# YTM32B1MD2 register map
Vendor: YTMicro; File version: 1.0
CPU: CM33 r0p4, little endian, MPU, FPU, 2 interrupt priority bits
Registers are 32-bit, read-write, reset 0x0 unless marked. A register's access mark holds for its fields unless they carry their own. Offsets are from the block's base; [hi:lo] are bit positions; {n}, {i} and the like mark numbered series; 'fields as' and 'values as' point back to an identical list; <NAME> marks a mode.

## EFM — Embedded Flash Module
Base 0x40010000; register names take the prefix EFM_
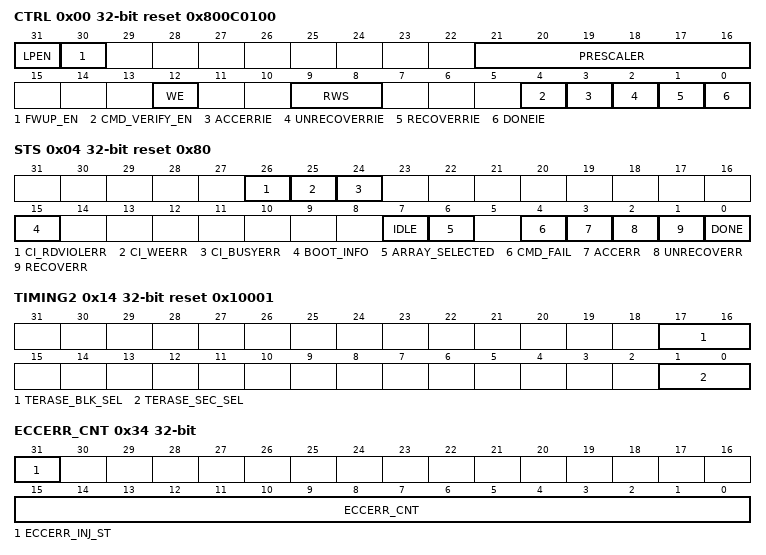
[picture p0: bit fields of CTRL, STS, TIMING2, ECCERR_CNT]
0x00 CTRL reset 0x800C0100
  [31] LPEN — This LPEN bit determines whether the Flash array will enter low power mode when the MCU send a low power request. ewline This field is reset by System Reset.
    0=Flash will keep active when the MCU send a low power request; 1=Flash will enter low power mode when the MCU send a low power request
  [30] FWUP_EN — This FWUP_EN bit determines whether enables fast wake-up of the Flash array. Power consumption of fast wake-up is bigger than normal wake-up. ewline This field is reset by System Reset.
    0=Flash wake-up time from Deep Standby mode is 20us; 1=Flash wake-up time from Deep Standby mode is 10us
  [21:16] PRESCALER — These PRESCALER bits are used for EFM operation time control. ewline Please use the following equation to calculate the PRESCALER value: ewline PRESCALER = Slow Bus Clock frequency / 2 ewline Round up if not divisible. ewline The unit of Slow Bus Clock frequency is Mhz. ewline For example, if Slow Bus Clock frequency is 40Mhz, PRESCALER value should be 20. ewline If Slow Bus Clock frequency is 23Mhz, PRESCALER value should be 12. ewline Please re-configure PRESCALER once the frequency is changed. ewline This field is reset by System Reset.
  [12] WE — This WE bit determines whether Flash is writable. Write Flash when WE is low causes bus error and STS[CI_WEERR] flag is set at the same time . ewline In the command operation flow, please set WE before AHB write and clear WE after AHB write . ewline This field is reset by System Reset.
    0=Disable Flash write; 1=Enable Flash write
  [9:8] RWS
    0=Valid value for core clk <= 40Mhz. in Normal Read mode; 1=Valid value for core clk <= 80Mhz. in Normal Read mode; 2=Valid value for core clk <= 100Mhz in Normal Read mode; 3=Valid value for core clk <= 100Mhz. in Normal Read mode
  [4] CMD_VERIFY_EN — This CMD_VERIFY_EN bit determines whether to do verify read after erase or program operation during executing a command. ewline - After each program cycle, if CMD_VERIFY_EN=1, EFM read the programmed address and compare the read data to program data. If not equal, set STS[CMD_FAIL] flag high ewline - After each erase cycle, if CMD_VERIFY_EN=1, EFM read the erased addresses and compare read data with FF. If read data are not all FF, set STS[CMD_FAIL] flag high. ewline This field is reset by System Reset.
    0=Disable verify read after erase or program cycle; 1=Enable verify read after erase or program cycle
  [3] ACCERRIE — This ACCERRIE bit determines whether the interrupt will be generated when STS[ACCERR] flag is asserted. ewline This field is reset by System Reset.
    0=Don't generate interrupt when STS[ACCERR] flag is asserted; 1=Generate interrupt when STS[ACCERR] flag is asserted
  [2] UNRECOVERRIE — This UNRECOVERRIE bit determines whether the interrupt will be generated when STS[UNRECOVERR] flag is asserted. ewline This field is reset by System Reset.
    0=Don't generate interrupt when STS[UNRECOVERR] flag is asserted; 1=Generate interrupt when STS[UNRECOVERR] flag is asserted
  [1] RECOVERRIE — This RECOVERRIE bit determines whether the interrupt will be generated when STS[RECOVERR] flag is asserted. ewline This field is reset by System Reset.
    0=Don't generate interrupt when STS[RECOVER] flag is asserted; 1=Generate interrupt when STS[RECOVERR] flag is asserted
  [0] DONEIE — This DONEIE bit determines whether the interrupt will be generated when DONE flag is asserted. ewline This field is reset by System Reset.
    0=Don't generate interrupt when STS[DONE] flag is asserted; 1=Generate interrupt when STS[DONE] flag is asserted
0x04 STS reset 0x80
  [26] CI_RDVIOLERR — This CI_RDVIOLERR bit indicates whether a read violation error is detected. Please check this bit after bus error. ewline Read violation error includes below scenarios: ewline - Read CUS_NVR sector when CUS_KEY is not set. ewline - Read HCU_NVR sector. ewline - Read BOOT_NVR sector. ewline This field is reset by System Reset.
  [25] CI_WEERR — Try to write Flash array when CTRL[WE] is disabled will cause bus error and set CI_WEERR flag. ewline This field is reset by System Reset.
  [24] CI_BUSYERR — Try to access Flash array when CTRL[IDLE] is 0 will cause bus error and set CI_BUSYERR flag. ewline This field is reset by System Reset.
  [15] BOOT_INFO ro — This BOOT_INFO bit indicates whether PFlash SoC address remap is enabled. ewline This field is reset by System Reset.
    0=PFlash SoC address remap is disabled, SoC boots code from A side; 1=PFlash SoC address remap is enabled, SoC boots code from B side. Refer to \hyperref[boot-swap-operation]{Boot-Swap Operation} for more details.
  [7] IDLE ro — This IDLE bit indicates whether EFM is busy executing a command or initializing or in low power mode. ewline IDLE bit may not be low immediately after writing a command because EFM needs to wait for core interface free before starting execute the command. This field is reset by System Reset.
    0=EFM is executing a command or initializing or in low power mode; 1=EFM is idle
  [6] ARRAY_SELECTED ro — Software should write target array address before launching a command. The write operation will set ARRAY_SELECTED flag after several cycles. ewline This field is reset by System Reset. ewline ote{Launching command when ARRAY_SELECTED=1 avoid access error caused by non-sequential scheduling of instructions.}
    0=The target Flash array is not selected. EFM is not ready to launch a command.; 1=The target Flash array is selected. EFM is ready to launch a command.
  [4] CMD_FAIL — This CMD_FAIL bit indicates whether the current command is failed. ewline ewline Command failure includes below scenarios: ewline - Read check before a program cycle failed if Flash line bits are not all FF. ewline - Verify check after an erase cycle failed if Flash line bits are not cleared to all FF. ewline - Verify check after a program cycle failed if program data not equal to read data. ewline ewline This field is reset by System Reset.
  [3] ACCERR — This ACCERR bit indicates whether an access error is detected. ewline This flag is set if detecting an error when write CMD register. ewline If an access error occurred, the command is not launched. ewline Access error scenarios refer to \hyperref[flash-abnormal-operation]{Flash Abnormal Operation}. ewline This field is reset by System Reset.
    0=Access error is not detected; 1=Access error is detected
  [2] UNRECOVERR — This UNRECOVERR bit indicates whether a 2-bit ECC error is detected during Flash read. ewline This field is reset by Power-on Reset.
    0=No un-recovery ECC error is detected; 1=At least one un-recovery ECC error is detected
  [1] RECOVERR — This RECOVERR bit indicates whether a 1-bit ECC error is detected during Flash read. ewline This field is reset by Power-on Reset.
    0=No recovery ECC error is detected; 1=At least one recovery error is detected
  [0] DONE — This DONE bit indicates whether the current command is completed. ewline This field is reset by System Reset.
    0=Current command is in progress or no command is launched; 1=Current command is completed
0x08 CMD
  [7:0] CMD — These CMD bits determine which commands are available. Write valid command code to CMD to launch a command. ewline Refer to table \hyperref[efm-commands]{EFM commands} for command code. ewline This field is reset by System Reset.
0x0C CMD_PROT
  [31:0] CMD_PROT — These CMD_PROT is used to disable commands. ewline If any bit of CMD_PROT is set high, its corresponding command is disabled. ewline Refer to \hyperref[efm-commands]{EFM commands} table for the map between commands and CMD_PROT bits ewline This field is reset by System Reset.
0x10 TIMING1 reset 0x1
  [1:0] TPROG_SEL — These TPROG_SEL bits indicate the program pulse time. ewline The valid program pulse time is from 5us to 6.5us. Specific program time is decided by TPROG_SEL by fixed step. ewline For example, if TPROG_SEL is 01, the Flash array program pulse time is 5.5us. ewline This register bit is reset by System Reset.
    0=Flash array program pulse time is 5us; 1=Flash array program pulse time is 5.5us; 2=Flash array program pulse time is 6us; 3=Flash array program pulse time is 6.5us
0x14 TIMING2 reset 0x10001
  [17:16] TERASE_BLK_SEL — These TERASE_BLK_SEL bits indicate the block erase pulse times. ewline The valid block erase pulse time is from 30ms to 40ms. Specific block erase time is decided by TERASE_BLK_SEL. ewline For example, if TERASE_BLK_SEL value is 01, the Flash array block erase pulse time is 34ms. ewline This register bit is reset by System Reset. ote{Please set TERASE_BLK_SEL register to valid value before send ERASE_BLOCK command.}
    0=Flash array block erase pulse time is 31ms; 1=Flash array block erase pulse time is 34ms; 2=Flash array block erase pulse time is 36ms; 3=Flash array block erase pulse time is 39ms
  [1:0] TERASE_SEC_SEL — These TERASE_SEC_SEL bits indicate the sector erase pulse times. ewline The valid block erase pulse time is from 2ms to 3ms. Specific block erase time is decided by TERASE_BLK_SEL. ewline For example, if TERASE_SEC_SEL value is 01, the Flash array sector erase pulse time is 2.4ms. ewline This register bit is reset by System Reset. ote{Please set TERASE_SEC_SEL register to valid value before send ERASE_SECTOR command.}
    0=Flash array sector erase pulse time is 2.1ms; 1=Flash array sector erase pulse time is 2.4ms; 2=Flash array sector erase pulse time is 2.6ms; 3=Flash array sector erase pulse time is 2.9ms
0x20 ERR_INJECT_CTRL
  [31:30] ECCERR_INJ_EN — Set this ECCERR_INJ_EN bits while cause 1-bit/ 2-bit ECC error for all Flash read out data. ewline Write ECCERR_INJ_EN will set ECCERR_INJ_ST high. And ECCERR_INJ_ST will auto clear when core interface is free. ewline Configuration to this field is valid only after ECCERR_INJ_ST goes from high to low. ewline This field is reset by System Reset.
    0=00b (Disable ECC error inject .); 1=01b (Inject 1-bit ECC error for any address.); 2=10b (Inject 1-bit ECC error for any address.); 3=11b (Inject 2-bit ECC error for any address.)
{0x24+4i} ADDR_PROT{i} reset 0xFFFFFFFF (i=0..2)
  [31:0] ADDR_PROT — Flash main array is divided into 32 partitions. Each partition is protected by one bit of ADDR_PROT. The size of each partition is 8KB. ewline All bits of ADDR_PROT is 1. If any bit of ADDR_PROT is clear to 0, its corresponding partition is under protection (read only). Erase or program to this protected partition is invalid. ewline EFM hardware initialization flow (STS[IDLE]=0) will load ADDR_PROT registers with initial values from CUS_NVR array if the CUS_NVR has programmed with initial ADDR_PROT values and Tag. ewline After EFM hardware initial done (STS[IDLE]=1), software can write 0 to any bit of ADDR_PROT, but can not write 1 to it. ewline This field is reset by System Reset.
0x30 ECCERR_ADDR reset 0xFFFFFFFF
  [31:0] ERR_FLASH_ADDR ro — These bits records the first detected ECC error address. Followed ECC error addresses are not recorded. ewline When detecting an ECC error, hardware will set ECC error flag (RECOVERR or UNRECOVERR) and record information about this error when ECCERR_ADDR is empty. ewline ECCERR_ADDR is cleared by writing 1 to the recorded RECOVERR or UNRECOVERR flag. For example, if ECCERR_ADDR records UNRECOVERR address information, only write 1 to UNRECOVERR can clear ECCERR_ADDR, writing 1 to RECOVERR can not clear ECCERR_ADDR. ewline Read ECCERR_ADDR to get SOC address of the recorded ECC error. ewline ECCERR_ADDR is aligned to 4Byte (i.e. 0x0, 0x4, 0x8, 0xC, 0x10, ......) because a FLash read get a 32-bit page data. Bus read 8-/16-bit data in address range ECCERR_ADDR~(ECCERR_ADDR+0x3) get the same ECC result. ewline This field is reset by Power-on Reset.
0x34 ECCERR_CNT
  [31] ECCERR_INJ_ST ro — This bit shows whether configuration of ERR_INJECT_CTRL is valid. ewline This bit is set when software write ERR_INJECT_CTRL register and is cleared by hardware when configuration in ERR_INJECT_CTRL is valid. ewline Software need to wait ECCERR_INJ_ST negative-edge after configuring ERR_INJECT_CTRL register.
    0=Hasn't configure ERR_INJECT_CTRL, or configuration in ERR_INJECT_CTRL is valid; 1=Configure ERR_INJECT_CTRL is on-going and configuration in ERR_INJECT_CTRL is invalid
  [15:0] ECCERR_CNT ro — These ECCERR_CNT bits record 1-bit ECC errors and 2-bit ECC errors . ewline This field is reset by Power-on Reset.
0x100 RSA_KEY_CFG reset 0x7F
  [6:0] RSA_KEY_NUM — These bits are used to set RSA_KEY number when executing command LOAD_RSA_KEY. ewline LOAD_RSA_KEY command will send ((RSA_KEY_NUM+1)*32) bit width RSA_KEY to HCU. ewline This field is reset by System Reset.
0x200 CMD_UNLOCK wo
  [31:0] CMD_UNLOCK_KEY — Please write 0xfd9573f5 before launching a command.
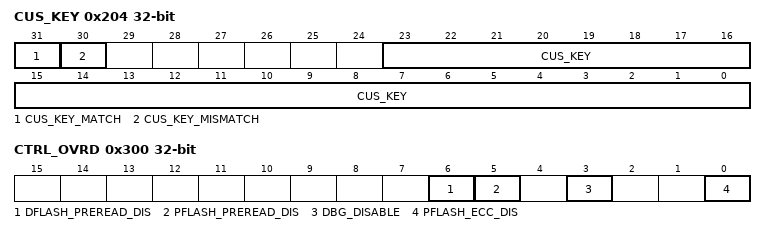
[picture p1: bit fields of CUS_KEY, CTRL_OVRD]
0x204 CUS_KEY
  [31] CUS_KEY_MATCH ro — This CUS_KEY_MATCH bit indicates whether Customer Key is matched. ewline Write CUS_KEY with correct value when both CUS_KEY_MATCH and CUS_KEY_MISMATCH are low will set this flag high. ewline When CUS_KEY_MATCH is high, write error value to CUS_KEY will clear this flag. ewline When CUS_KEY_MISMATCH is high, this flag is low until a reset happened. ewline This field is reset by System Reset.
    0=Customer Key is not matched; 1=Customer Key is matched
  [30] CUS_KEY_MISMATCH ro — This CUS_KEY_MISMATCH bit indicates whether Customer Key is mis-matched. ewline Write CUS_KEY with error value when both CUS_KEY_MATCH and CUS_KEY_MISMATCH are low will set this bit to high. ewline When CUS_KEY_MISMATCH is high, CUS_KEY configuration is blocked. ewline This field is reset by Power-on Reset.
    0=Customer Key is matched; 1=Customer Key is not matched
  [23:0] CUS_KEY wo — Following are Customer Key protected operations, please write CUS_KEY with correct value before doing these operations: ewline - Read or erase or program CUS_NVR ewline - Erase HCU_NVR array if it is exist ewline Default Customer Key value is 0x4DFF32 and the Customer Key value can be overridden by programming the first address of CUS_NVR and then reset EFM.
0x300 CTRL_OVRD
  [6] DFLASH_PREREAD_DIS wo — When executing a program command, EFM will read DFlash and check if the target address is erased empty before send a program pulse. If target address is not empty, no program pulse is send to DFlash. The program command failed. ewline A method to inject ECC error into Flash array, software can set PREREAD_DIS=1 and then program a Flash line twice with different data. ewline This field is reset by System Reset.
    0=Pre-read function is enabled before send a program pulse; 1=Pre-read function is disabled before send a program pulse
  [5] PFLASH_PREREAD_DIS wo — When executing a program command, EFM will read Flash and check if the target address is erased empty before send a program pulse. If target address is not empty, no program pulse is send to PFlash. The program command failed. ewline To inject ECC error into Flash array, software can set PREREAD_DIS=1 and then program a Flash line twice with different data. ewline This field is reset by System Reset.
    values as DFLASH_PREREAD_DIS
  [3] DBG_DISABLE wo — This bit determines whether the debugger is disabled. ewline This register bit is write protected by CUS_KEY. ewline This field is reset by System Reset.
    0=Debugger is enabled; 1=Debugger is disabled
  [0] PFLASH_ECC_DIS wo — This bit determines whether PFlash ECC Decoder is disabled. ewline This field is reset by Power-on Reset.

## Notices in the file
YTMicro Microcontroller all rights reserved.
